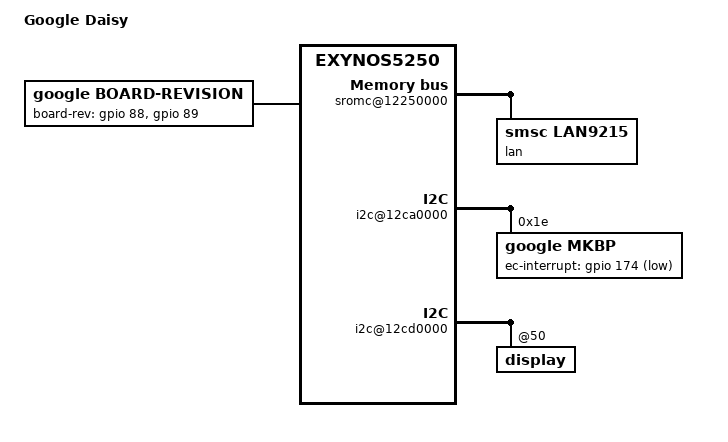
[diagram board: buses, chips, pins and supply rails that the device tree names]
/*
 * Google Daisy board device tree source
 *
 * Copyright (c) 2012 Google, Inc
 *
 * This program is free software; you can redistribute it and/or modify
 * it under the terms of the GNU General Public License version 2 as
 * published by the Free Software Foundation.
*/

/dts-v1/;
/include/ "exynos5250.dtsi"
/include/ "flashmap-exynos-ro.dtsi"
/include/ "flashmap-4mb-rw.dtsi"
/include/ "chromeos-exynos.dtsi"
/include/ "cros5250-common.dtsi"

/ {
	model = "Google Daisy";
	compatible = "google,daisy", "samsung,smdk5250", "samsung,exynos5250";

	board-rev {
		compatible = "google,board-revision";
		google,board-rev-gpios = <&gpio 88 0>, <&gpio 89 0>;
	};

	sromc@12250000 {
		bank = <3>;
		srom-timing = <1 9 12 1 6 1 1>;
		width = <2>;
		lan@7000000 {
			compatible = "smsc,lan9215", "smsc,lan";
			reg = <0x7000000 0x100>;
			phy-mode = "mii";
		};
	};

	i2c@12ca0000 {
		mkbp@1e {
			reg = <0x1e>;
			compatible = "google,mkbp";
			i2c-max-frequency = <100000>;
			ec-interrupt = <&gpio 174 1>;
		};
	};

	i2c@12cd0000 {
		display@50 {
			edid = /bits/ 8 <
				0x00 0xff 0xff 0xff 0xff 0xff 0xff 0x00
				0x06 0xaf 0x5c 0x30 0x00 0x00 0x00 0x00
				0x00 0x15 0x01 0x04 0x90 0x1a 0x0e 0x78
				0x02 0x99 0x85 0x95 0x55 0x56 0x92 0x28
				0x22 0x50 0x54 0x00 0x00 0x00 0x01 0x01
				0x01 0x01 0x01 0x01 0x01 0x01 0x01 0x01
				0x01 0x01 0x01 0x01 0x01 0x01 0x58 0x1b
				0x56 0x68 0x50 0x00 0x19 0x30 0x30 0x20
				0x36 0x00 0x00 0x90 0x10 0x00 0x00 0x1a
				0x58 0x1b 0x56 0x68 0x50 0x00 0x19 0x30
				0x30 0x20 0x36 0x00 0x00 0x90 0x10 0x00
				0x00 0x1a 0x00 0x00 0x00 0xfe 0x00 0x32
				0x56 0x44 0x32 0x4b 0x81 0x42 0x31 0x31
				0x36 0x58 0x57 0x33 0x00 0x00 0x00 0x00
				0x00 0x00 0x41 0x0a 0x96 0x01 0x11 0x00
				0x00 0x02 0x01 0x0a 0x20 0x20 0x00 0xb3>;
		};
	};

	dmc@10C00000 {
		mem-manuf = "samsung";
	};

	dp@145b0000 {
		samsung,interface = "mipi";
	};
};
